# phy_pma_lane_registers: IP-XACT component
VLNV cadence:cdns_lib:phy_pma_lane_registers:1685-2009

## Address spaces and blocks
sd3101_t4_registers.sd3101_phy_registers: base 0x3c000, range 0x3ff, width 32

## Registers
Registers are 32-bit, read-write, reset 0x0 unless marked. A register's access mark holds for its fields unless they carry their own. Offsets are from the block's base; lines under a group give offsets from that group; [hi:lo] are bit positions; {n}, {i} and the like mark numbered series; 'fields as' and 'values as' point back to an identical list; <NAME> marks a mode.

## sd3101_t4_registers.sd3101_phy_registers
Base 0x0003C000
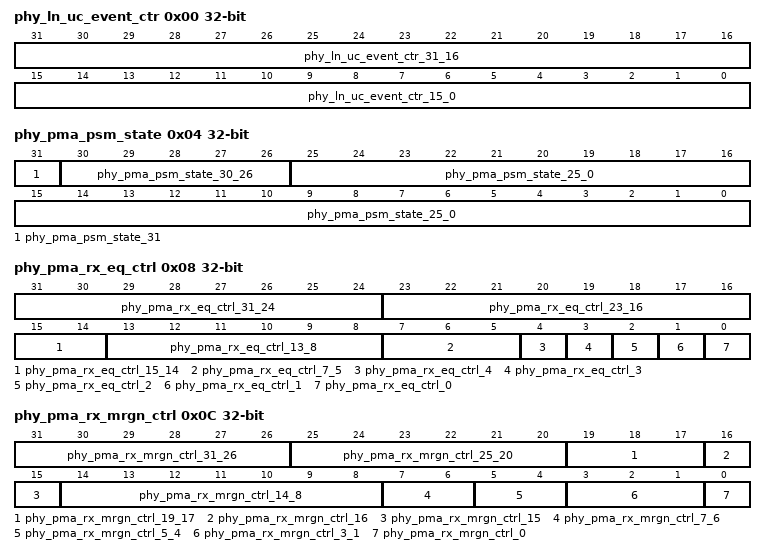
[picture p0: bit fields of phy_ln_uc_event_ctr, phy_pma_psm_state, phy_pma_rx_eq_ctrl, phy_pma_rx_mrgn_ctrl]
0x00 phy_ln_uc_event_ctr — PHY lane-level uC event counter register
  [31:16] phy_ln_uc_event_ctr_31_16 ro — RSVD
  [15:0] phy_ln_uc_event_ctr_15_0 ro — EVENT_CNT
0x04 phy_pma_psm_state — PMA PSM state register
  [31] phy_pma_psm_state_31 ro — PSM_RDY
  [30:26] phy_pma_psm_state_30_26 ro — RSVD
  [25:0] phy_pma_psm_state_25_0 ro — PSM_ST
0x08 phy_pma_rx_eq_ctrl — PMA RX equalization control register
  [31:24] phy_pma_rx_eq_ctrl_31_24 ro — RSVD2
  [23:16] phy_pma_rx_eq_ctrl_23_16 — FOM
  [15:14] phy_pma_rx_eq_ctrl_15_14 ro — RSVD1
  [13:8] phy_pma_rx_eq_ctrl_13_8 — DIR_CHG
  [7:5] phy_pma_rx_eq_ctrl_7_5 ro — RSVD0
  [4] phy_pma_rx_eq_ctrl_4 — RXINVALID_REQ
  [3] phy_pma_rx_eq_ctrl_3 — RXEQEVAL
  [2] phy_pma_rx_eq_ctrl_2 — RXEQEVAL_CMP
  [1] phy_pma_rx_eq_ctrl_1 — RXEQEVAL_STS
  [0] phy_pma_rx_eq_ctrl_0 ro — RXEQEVAL_EN
0x0C phy_pma_rx_mrgn_ctrl — PMA RX margining control register
  [31:26] phy_pma_rx_mrgn_ctrl_31_26 ro — RSVD4
  [25:20] phy_pma_rx_mrgn_ctrl_25_20 — ERR_CNT
  [19:17] phy_pma_rx_mrgn_ctrl_19_17 ro — RSVD3
  [16] phy_pma_rx_mrgn_ctrl_16 — VALID
  [15] phy_pma_rx_mrgn_ctrl_15 ro — RSVD2
  [14:8] phy_pma_rx_mrgn_ctrl_14_8 ro — OFFSET
  [7:6] phy_pma_rx_mrgn_ctrl_7_6 ro — RSVD1
  [5:4] phy_pma_rx_mrgn_ctrl_5_4 ro — DIR
  [3:1] phy_pma_rx_mrgn_ctrl_3_1 ro — RSVD0
  [0] phy_pma_rx_mrgn_ctrl_0 ro — REQ
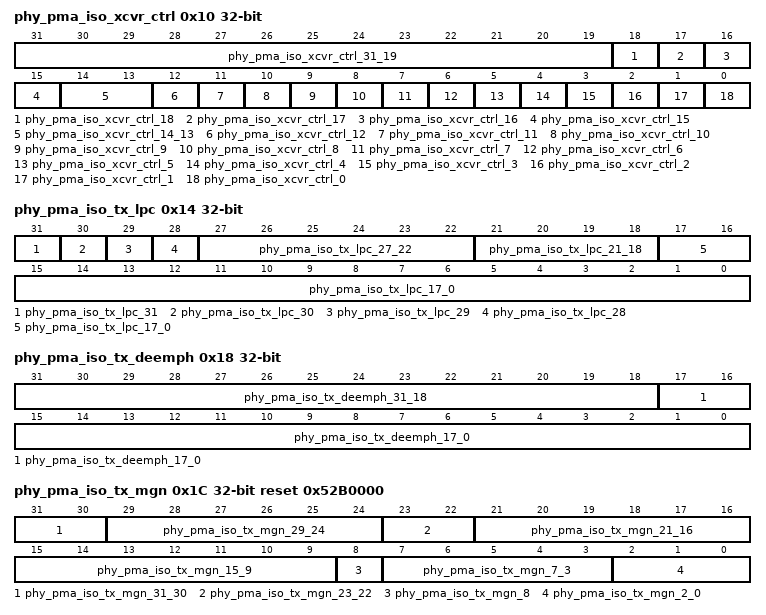
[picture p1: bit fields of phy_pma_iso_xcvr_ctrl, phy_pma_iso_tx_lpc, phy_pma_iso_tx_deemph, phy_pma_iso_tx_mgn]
0x10 phy_pma_iso_xcvr_ctrl — PMA Isolation Transceiver control register
  [31:19] phy_pma_iso_xcvr_ctrl_31_19 ro — RSVD5
  [18] phy_pma_iso_xcvr_ctrl_18 — TX_LFPS_MODE
  [17] phy_pma_iso_xcvr_ctrl_17 — TX_LFPS_EN
  [16] phy_pma_iso_xcvr_ctrl_16 — EQ_TRN_DATA_VLD
  [15] phy_pma_iso_xcvr_ctrl_15 ro — PLLCLKEN_ACK
  [14:13] phy_pma_iso_xcvr_ctrl_14_13 ro — RSVD4
  [12] phy_pma_iso_xcvr_ctrl_12 — TX_ELEC_IDL
  [11] phy_pma_iso_xcvr_ctrl_11 ro — RCVDETECTED
  [10] phy_pma_iso_xcvr_ctrl_10 ro — RCVDET_DN
  [9] phy_pma_iso_xcvr_ctrl_9 — RCVDET_EN
  [8] phy_pma_iso_xcvr_ctrl_8 — LINK_RST
  [7] phy_pma_iso_xcvr_ctrl_7 — PLLCLKEN
  [6] phy_pma_iso_xcvr_ctrl_6 ro — RSVD3
  [5] phy_pma_iso_xcvr_ctrl_5 — LN_SUSPEND
  [4] phy_pma_iso_xcvr_ctrl_4 ro — RSVD2
  [3] phy_pma_iso_xcvr_ctrl_3 ro — RX_SIGDET
  [2] phy_pma_iso_xcvr_ctrl_2 ro — RSVD1
  [1] phy_pma_iso_xcvr_ctrl_1 — RX_TERM
  [0] phy_pma_iso_xcvr_ctrl_0 ro — RSVD0
0x14 phy_pma_iso_tx_lpc — PMA Isolation transmitter local preset coefficient register
  [31] phy_pma_iso_tx_lpc_31 ro — PRESET_VLD
  [30] phy_pma_iso_tx_lpc_30 ro — RSVD1
  [29] phy_pma_iso_tx_lpc_29 — GET_INIT_COEF
  [28] phy_pma_iso_tx_lpc_28 — GET_PRE- SET_COEF
  [27:22] phy_pma_iso_tx_lpc_27_22 — PRESET_INDEX
  [21:18] phy_pma_iso_tx_lpc_21_18 ro — RSVD0
  [17:0] phy_pma_iso_tx_lpc_17_0 ro — PRESET_COEF
0x18 phy_pma_iso_tx_deemph — PMA Tx deemphasis isolation register
  [31:18] phy_pma_iso_tx_deemph_31_18 ro — RSVD
  [17:0] phy_pma_iso_tx_deemph_17_0 — TX_DEEMPH
0x1C phy_pma_iso_tx_mgn reset 0x52B0000 — PMA Tx margin isolation register
  [31:30] phy_pma_iso_tx_mgn_31_30 ro — RSVD3
  [29:24] phy_pma_iso_tx_mgn_29_24 ro — TX_LOCAL_LF
  [23:22] phy_pma_iso_tx_mgn_23_22 ro — RSVD2
  [21:16] phy_pma_iso_tx_mgn_21_16 ro — TX_LOCAL_FS
  [15:9] phy_pma_iso_tx_mgn_15_9 ro — RSVD1
  [8] phy_pma_iso_tx_mgn_8 — TX_SWING
  [7:3] phy_pma_iso_tx_mgn_7_3 ro — RSVD0
  [2:0] phy_pma_iso_tx_mgn_2_0 — TX_VMGN
0x20 phy_pma_iso_tx_data — PMA TX data isolation register
  [31:0] phy_pma_iso_tx_data_31_0 — VALUE
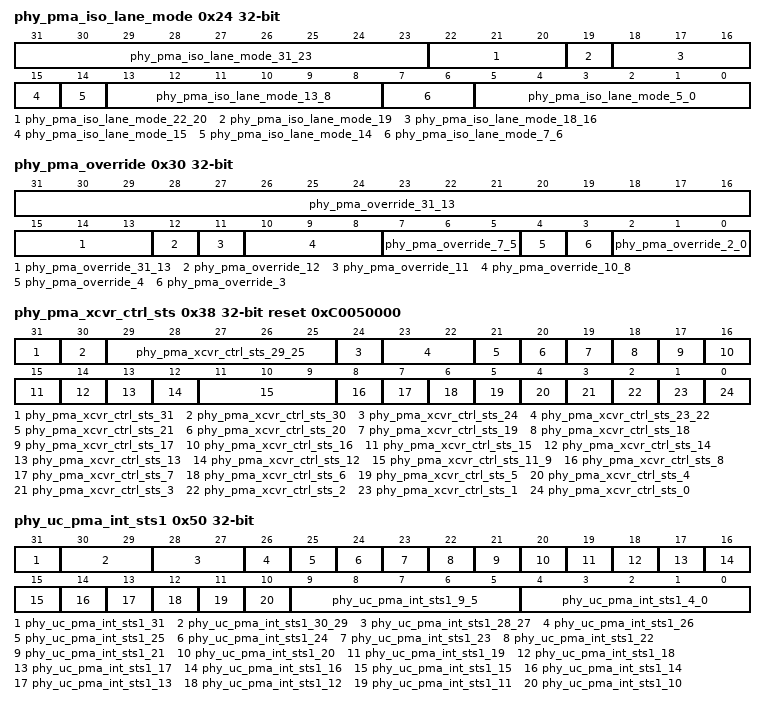
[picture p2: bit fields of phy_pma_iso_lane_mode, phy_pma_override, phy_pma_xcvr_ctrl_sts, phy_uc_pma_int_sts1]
0x24 phy_pma_iso_lane_mode — PHY_PMA lane mode isolation register
  [31:23] phy_pma_iso_lane_mode_31_23 ro — RSVD
  [22:20] phy_pma_iso_lane_mode_22_20 — STD_MD
  [19] phy_pma_iso_lane_mode_19 ro — RSVD
  [18:16] phy_pma_iso_lane_mode_18_16 — WIDTH
  [15] phy_pma_iso_lane_mode_15 ro — RSVD
  [14] phy_pma_iso_lane_mode_14 — SIGDET_EN_EXT
  [13:8] phy_pma_iso_lane_mode_13_8 ro — PWRST_ACK
  [7:6] phy_pma_iso_lane_mode_7_6 ro — RSVD
  [5:0] phy_pma_iso_lane_mode_5_0 — PWRST_REQ
0x2C phy_pma_iso_rx_data — PMA RX data isolation register
  [31:0] phy_pma_iso_rx_data_31_0 ro — VALUE
0x30 phy_pma_override — PMA override register
  [31:13] phy_pma_override_31_13 ro — RSVD3
  [12] phy_pma_override_12 — WIDTH_OVD_EN
  [11] phy_pma_override_11 ro — RSVD2
  [10:8] phy_pma_override_10_8 — WIDTH_OVD_VAL
  [7:5] phy_pma_override_7_5 ro — RSVD1
  [4] phy_pma_override_4 — STD_MD_OVD_EN
  [3] phy_pma_override_3 ro — RSVD0
  [2:0] phy_pma_override_2_0 — STD_MD_OVD_VAL
0x38 phy_pma_xcvr_ctrl_sts reset 0xC0050000 — PMA transceiver control and status register
  [31] phy_pma_xcvr_ctrl_sts_31 write-1-sets — TX_RESET
  [30] phy_pma_xcvr_ctrl_sts_30 write-1-sets — RX_RESET
  [29:25] phy_pma_xcvr_ctrl_sts_29_25 ro — RSVD3
  [24] phy_pma_xcvr_ctrl_sts_24 write-1-sets — TX_DMPH_OVD
  [23:22] phy_pma_xcvr_ctrl_sts_23_22 ro — RSVD2
  [21] phy_pma_xcvr_ctrl_sts_21 write-1-sets — PWRST_AUTO_MASK
  [20] phy_pma_xcvr_ctrl_sts_20 write-1-sets — RXERR_INJ
  [19] phy_pma_xcvr_ctrl_sts_19 write-1-sets — TXERR_INJ
  [18] phy_pma_xcvr_ctrl_sts_18 write-1-sets — SIGDET_MASK
  [17] phy_pma_xcvr_ctrl_sts_17 write-1-sets — TX_IDL_MASK
  [16] phy_pma_xcvr_ctrl_sts_16 write-1-sets — PWRST_MASK
  [15] phy_pma_xcvr_ctrl_sts_15 ro — CDRLF_LOCK
  [14] phy_pma_xcvr_ctrl_sts_14 ro — RXBIST_STS
  [13] phy_pma_xcvr_ctrl_sts_13 ro — RXBIST_TGL
  [12] phy_pma_xcvr_ctrl_sts_12 ro — RXBIST_SYNC
  [11:9] phy_pma_xcvr_ctrl_sts_11_9 ro — RSVD1
  [8] phy_pma_xcvr_ctrl_sts_8 write-1-sets — LN_SUSPEND
  [7] phy_pma_xcvr_ctrl_sts_7 ro — RSVD1
  [6] phy_pma_xcvr_ctrl_sts_6 write-1-sets — RECCLK_LPBK
  [5] phy_pma_xcvr_ctrl_sts_5 write-1-sets — LINE_LPBK
  [4] phy_pma_xcvr_ctrl_sts_4 write-1-sets — SER_LPBK
  [3] phy_pma_xcvr_ctrl_sts_3 ro — RSVD0
  [2] phy_pma_xcvr_ctrl_sts_2 write-1-sets — TX_DIFF_INV
  [1] phy_pma_xcvr_ctrl_sts_1 write-1-sets — RX_DIFF_INV
  [0] phy_pma_xcvr_ctrl_sts_0 write-1-sets — TXBIST_HOLD
0x3C phy_pma_xcvr_ctrl_sts_clr reset 0xC0050000 — PMA transceiver control and status clear register
  [31:0] phy_pma_xcvr_ctrl_sts_clr_31_0 write-1-clears — CLR
0x50 phy_uc_pma_int_sts1 — PHY uController PMA interrupt status 1 register
  [31] phy_uc_pma_int_sts1_31 write-1-clears — APB_TO
  [30:29] phy_uc_pma_int_sts1_30_29 write-1-clears — LN_TOP_API
  [28:27] phy_uc_pma_int_sts1_28_27 write-1-clears — LN_SOC_API
  [26] phy_uc_pma_int_sts1_26 write-1-clears — PS_ACK_CHG0_5
  [25] phy_uc_pma_int_sts1_25 write-1-clears — PS_REQ_CHG0_5
  [24] phy_uc_pma_int_sts1_24 write-1-clears — RXEQEVAL_FALL
  [23] phy_uc_pma_int_sts1_23 write-1-clears — RXEQEVAL_RISE
  [22] phy_uc_pma_int_sts1_22 write-1-clears — RXEQEVAL_FALL
  [21] phy_uc_pma_int_sts1_21 write-1-clears — RXEQEVAL_RISE
  [20] phy_uc_pma_int_sts1_20 write-1-clears — SIGDET_FALL
  [19] phy_uc_pma_int_sts1_19 write-1-clears — SIGDET_RISE
  [18] phy_uc_pma_int_sts1_18 write-1-clears — GET_COEFF
  [17] phy_uc_pma_int_sts1_17 write-1-clears — TXEI_FALL
  [16] phy_uc_pma_int_sts1_16 write-1-clears — TXEI_RISE
  [15] phy_uc_pma_int_sts1_15 write-1-clears — RCVDET_EN
  [14] phy_uc_pma_int_sts1_14 write-1-clears — CLKENACK_FALL
  [13] phy_uc_pma_int_sts1_13 write-1-clears — CLKENACK_RISE
  [12] phy_uc_pma_int_sts1_12 write-1-clears — CLKEN_FALL
  [11] phy_uc_pma_int_sts1_11 write-1-clears — CLKEN_RISE
  [10] phy_uc_pma_int_sts1_10 write-1-clears — STD_MD_CHG
  [9:5] phy_uc_pma_int_sts1_9_5 write-1-clears — PS_ACK_CHG0_4
  [4:0] phy_uc_pma_int_sts1_4_0 write-1-clears — PS_REQ_CHG0_4
0x54 phy_uc_pma_int_sts1_set — PHY uController PMA interrupt status 1 set register
  [31:0] phy_uc_pma_int_sts1_set_31_0 write-1-sets — SET
0x58 phy_ln_uc_pma_int_sts1_en — PHY lane-level uController PMA interrupt status 1 enable register (#)
  [31:0] phy_ln_uc_pma_int_sts1_en_31_0 — LN_ENABLE
0x5C phy_top_uc_pma_int_sts1_en — PHY top-level uController PMA interrupt status 1 enable register
  [31:0] phy_top_uc_pma_int_sts1_en_31_0 — TOP_ENABLE
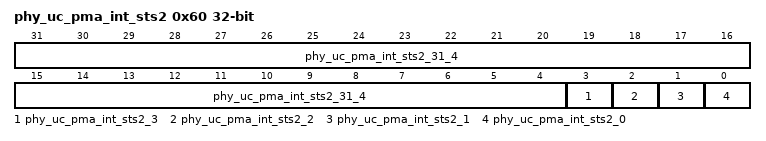
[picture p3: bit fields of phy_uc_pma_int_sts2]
0x60 phy_uc_pma_int_sts2 — PHY uController PMA interrupt status 2 register
  [31:4] phy_uc_pma_int_sts2_31_4 write-1-clears — RSVD
  [3] phy_uc_pma_int_sts2_3 write-1-clears — RX_TRAIN_FALL
  [2] phy_uc_pma_int_sts2_2 write-1-clears — RX_TRAIN_RISE
  [1] phy_uc_pma_int_sts2_1 write-1-clears — RX_INVALID_FALL
  [0] phy_uc_pma_int_sts2_0 write-1-clears — RX_INVALID_RISE
0x64 phy_uc_pma_int_sts2_set — PHY uController PMA interrupt status 2 set register
  [31:0] phy_uc_pma_int_sts2_set_31_0 write-1-sets — SET
0x70 phy_ln_uc_pma_en_int_sts1 — PHY lane uController PMA enabled interrupt status 1 register (#)
  [31:0] phy_ln_uc_pma_en_int_sts1_31_0 ro — ENBLD_INT_LN
0x74 phy_top_uc_pma_en_int_sts1 — PHY lane uController PMA enabled interrupt status 1 register
  [31:0] phy_top_uc_pma_en_int_sts1_31_0 ro — ENBLD_INT_TOP
0x78 phy_ln_uc_pma_en_int_sts2 — PHY lane uController PMA enabled interrupt status 2 register (#)
  [31:0] phy_ln_uc_pma_en_int_sts2_31_0 ro — ENBLD_INT_LN
0x7C phy_top_uc_pma_en_int_sts2 — PHY lane uController PMA enabled interrupt status 2 register
  [31:0] phy_top_uc_pma_en_int_sts2_31_0 ro — ENBLD_INT_TOP
{0x60+4i} uc_ln_scrpad{i} (i=8..15) — PHY lane uController scratchpad/mailbox {i} register
  [31:0] uc_ln_scrpad{i}_31_0 — VALUE
